# ATmega16A register map
Vendor: Atmel; File version: 1.0
CPU: other r0p0, little endian, no MPU, no FPU, 4 interrupt priority bits
Registers are 8-bit, read-write, reset 0x0 unless marked. A register's access mark holds for its fields unless they carry their own. Offsets are from the block's base; [hi:lo] are bit positions; {n}, {i} and the like mark numbered series; 'fields as' and 'values as' point back to an identical list.

## BOOT_LOAD — Bootloader
Base 0x00000057
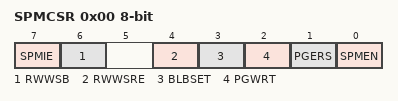
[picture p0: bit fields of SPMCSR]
0x00 SPMCSR — Store Program Memory Control Register
  [7] SPMIE — SPM Interrupt Enable
  [6] RWWSB — Read While Write Section Busy
  [4] RWWSRE — Read While Write section read enable
  [3] BLBSET — Boot Lock Bit Set
  [2] PGWRT — Page Write
  [1] PGERS — Page Erase
  [0] SPMEN — Store Program Memory Enable

## CPU — CPU Registers
Base 0x00000050
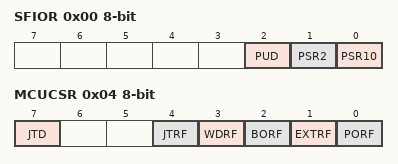
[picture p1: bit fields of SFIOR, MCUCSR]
0x00 SFIOR — Special function I/O register
  [2] PUD — Pull-up Disable
  [1] PSR2 — Prescaler reset
  [0] PSR10 — Prescaler reset
0x01 OSCCAL — Oscillator Calibration Value
  [7:0] OSCCAL — Oscillator Calibration
0x04 MCUCSR — MCU Control And Status Register
  [7] JTD — JTAG Interface Disable
  [4] JTRF — JTAG Reset Flag
  [3] WDRF — Watchdog Reset Flag
  [2] BORF — Brown-out Reset Flag
  [1] EXTRF — External Reset Flag
  [0] PORF — Power-on reset flag
0x05 MCUCR — MCU Control Register
  [6] SE — Sleep Enable
  [7:4] SM — Sleep Mode Select
    0=IDLE; 1=ADC (ADC Noise Reduction (If Available)); 2=PDOWN (Power Down); 3=PSAVE (Power Save); 10=STDBY (Standby); 11=ESTDBY (Extended Standby)
  [3:2] ISC1 — Interrupt Sense Control 1 Bits
    0=LOW_LEVEL_OF_INTX; 1=ANY_LOGICAL_CHANGE_IN_INTX; 2=FALLING_EDGE_OF_INTX; 3=RISING_EDGE_OF_INTX
  [1:0] ISC0 — Interrupt Sense Control 0 Bits
    values as ISC1

## EEPROM
Base 0x0000003C
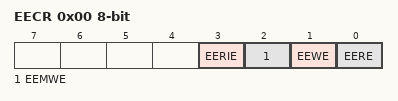
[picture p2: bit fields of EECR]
0x00 EECR — EEPROM Control Register
  [3] EERIE — EEPROM Ready Interrupt Enable
  [2] EEMWE — EEPROM Master Write Enable
  [1] EEWE — EEPROM Write Enable
  [0] EERE — EEPROM Read Enable
0x01 EEDR — EEPROM Data Register
  [7:0] EEDR — EEPROM Data bits
0x02 EEAR 16-bit (reset mask 0xFF) — EEPROM Address Register Bytes
  [8:0] EEAR — EEPROM Address bits

## EXINT — External Interrupts
Base 0x00000054
0x00 MCUCSR — MCU Control And Status Register
  [6] ISC2 — Interrupt Sense Control 2
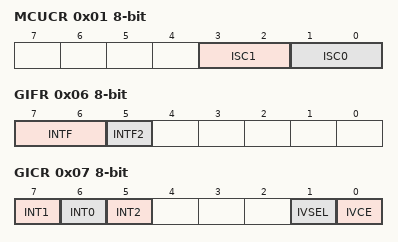
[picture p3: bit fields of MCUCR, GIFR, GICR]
0x01 MCUCR — General Interrupt Control Register
  [3:2] ISC1 — Interrupt Sense Control 1 Bits
    0=LOW_LEVEL_OF_INTX; 1=ANY_LOGICAL_CHANGE_OF_INTX; 2=FALLING_EDGE_OF_INTX; 3=RISING_EDGE_OF_INTX
  [1:0] ISC0 — Interrupt Sense Control 0 Bits
    values as ISC1
0x06 GIFR — General Interrupt Flag Register
  [7:6] INTF — External Interrupt Flags
  [5] INTF2 — External Interrupt Flag 2
0x07 GICR — General Interrupt Control Register
  [7] INT1 — External Interrupt Request 1 Enable
  [6] INT0 — External Interrupt Request 0 Enable
  [5] INT2 — External Interrupt Request 2 Enable
  [1] IVSEL — Interrupt Vector Select
  [0] IVCE — Interrupt Vector Change Enable

## JTAG — JTAG Interface
Base 0x00000051
0x00 OCDR — On-Chip Debug Related Register in I/O Memory
  [7:0] OCDR — On-Chip Debug Register Bits
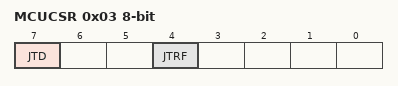
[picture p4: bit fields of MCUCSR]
0x03 MCUCSR — MCU Control And Status Register
  [7] JTD — JTAG Interface Disable
  [4] JTRF — JTAG Reset Flag

## LOCKBIT — Lockbits
Base 0x00000000
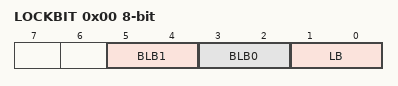
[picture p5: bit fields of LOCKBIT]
0x00 LOCKBIT
  [5:4] BLB1 — Boot Loader Protection Mode
    0=LPM_SPM_DISABLE (LPM and SPM prohibited in Boot Section); 1=LPM_DISABLE (LPM prohibited in Boot Section); 2=SPM_DISABLE (SPM prohibited in Boot Section); 3=NO_LOCK (No lock on SPM and LPM in Boot Section)
  [3:2] BLB0 — Boot Loader Protection Mode
    0=LPM_SPM_DISABLE (LPM and SPM prohibited in Application Section); 1=LPM_DISABLE (LPM prohibited in Application Section); 2=SPM_DISABLE (SPM prohibited in Application Section); 3=NO_LOCK (No lock on SPM and LPM in Application Section)
  [1:0] LB — Memory Lock
    0=PROG_VER_DISABLED (Further programming and verification disabled); 2=PROG_DISABLED (Further programming disabled); 3=NO_LOCK (No memory lock features enabled)

## PORTA — I/O Port
Base 0x00000039
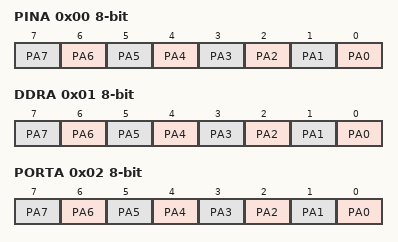
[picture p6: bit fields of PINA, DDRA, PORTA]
0x00 PINA — Port A Input Pins
  [n] PA{n} (n=0..7) — Pin A{n}
0x01 DDRA — Port A Data Direction Register
  [n] PA{n} (n=0..7) — Pin A{n}
0x02 PORTA — Port A Data Register
  [n] PA{n} (n=0..7) — Pin A{n}
